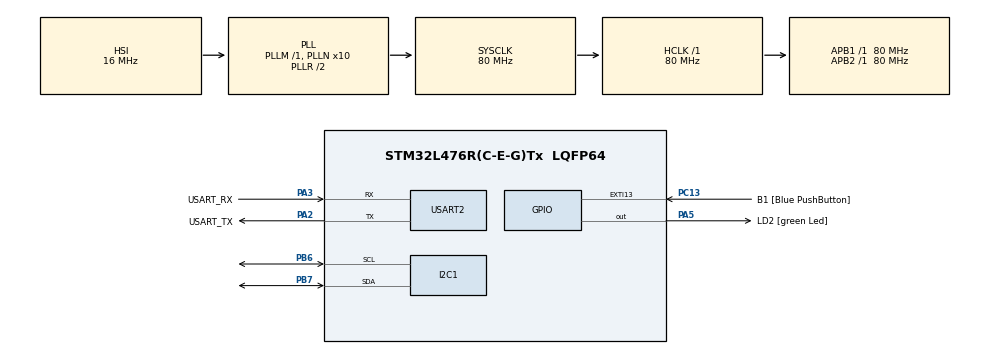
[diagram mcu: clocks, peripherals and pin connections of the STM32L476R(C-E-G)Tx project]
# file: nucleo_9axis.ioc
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Mcu.Family=STM32L4
Mcu.Name=STM32L476R(C-E-G)Tx
Mcu.Package=LQFP64
NVIC.PriorityGroup=NVIC_PRIORITYGROUP_4
PA13\ (JTMS-SWDIO).GPIO_Label=TMS
PA13\ (JTMS-SWDIO).Mode=Serial_Wire
PA13\ (JTMS-SWDIO).Signal=SYS_JTMS-SWDIO
PA14\ (JTCK-SWCLK).GPIO_Label=TCK
PA14\ (JTCK-SWCLK).Mode=Serial_Wire
PA14\ (JTCK-SWCLK).Signal=SYS_JTCK-SWCLK
PA2.GPIO_Label=USART_TX
PA2.GPIO_Mode=GPIO_MODE_AF_PP
PA2.GPIO_PuPd=GPIO_NOPULL
PA2.GPIO_Speed=GPIO_SPEED_FREQ_VERY_HIGH
PA2.Mode=Asynchronous
PA2.Signal=USART2_TX
PA3.GPIO_Label=USART_RX
PA3.GPIO_Mode=GPIO_MODE_AF_PP
PA3.GPIO_PuPd=GPIO_NOPULL
PA3.GPIO_Speed=GPIO_SPEED_FREQ_VERY_HIGH
PA3.Mode=Asynchronous
PA3.Signal=USART2_RX
PA5.GPIO_Label=LD2 [green Led]
PA5.GPIO_ModeDefaultOutputPP=GPIO_MODE_OUTPUT_PP
PA5.GPIO_PuPd=GPIO_NOPULL
PA5.GPIO_Speed=GPIO_SPEED_FREQ_LOW
PA5.Signal=GPIO_Output
PB3\ (JTDO-TRACESWO).GPIO_Label=SWO
PB3\ (JTDO-TRACESWO).Signal=SYS_JTDO-SWO
PB6.Mode=I2C
PB6.Signal=I2C1_SCL
PB7.Mode=I2C
PB7.Signal=I2C1_SDA
PC13.GPIO_Label=B1 [Blue PushButton]
PC13.GPIO_ModeDefaultEXTI=GPIO_MODE_IT_FALLING
PC13.GPIO_PuPd=GPIO_NOPULL
PC13.Signal=GPXTI13
PC14-OSC32_IN\ (PC14).Mode=LSE-External-Oscillator
PC14-OSC32_IN\ (PC14).Signal=RCC_OSC32_IN
PC15-OSC32_OUT\ (PC15).Mode=LSE-External-Oscillator
PC15-OSC32_OUT\ (PC15).Signal=RCC_OSC32_OUT
PH0-OSC_IN\ (PH0).Signal=RCC_OSC_IN
PH1-OSC_OUT\ (PH1).Signal=RCC_OSC_OUT
ProjectManager.HeapSize=0x200
ProjectManager.StackSize=0x400
ProjectManager.TargetToolchain=Makefile
RCC.ADCFreq_Value=64000000
RCC.AHBFreq_Value=80000000
RCC.APB1Freq_Value=80000000
RCC.APB1TimFreq_Value=80000000
RCC.APB2Freq_Value=80000000
RCC.APB2TimFreq_Value=80000000
RCC.CortexFreq_Value=80000000
RCC.HCLKFreq_Value=80000000
RCC.HSE_VALUE=8000000
RCC.HSI_VALUE=16000000
RCC.MSI_VALUE=4000000
RCC.PLLN=10
RCC.PLLSourceVirtual=RCC_PLLSOURCE_HSI
RCC.PREFETCH_ENABLE=1
RCC.SYSCLKFreq_VALUE=80000000
RCC.SYSCLKSource=RCC_SYSCLKSOURCE_PLLCLK
RCC.USBFreq_Value=64000000
RCC.VCOOutputFreq_Value=160000000
USART2.VirtualMode-Asynchronous=VM_ASYNC
board=NUCLEO-L476RG

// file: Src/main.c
/**
  ******************************************************************************
  * @file           : main.c
  * @brief          : Main program body
  ******************************************************************************
  ** This notice applies to any and all portions of this file
  * that are not between comment pairs USER CODE BEGIN and
  * USER CODE END. Other portions of this file, whether
  * inserted by the user or by software development tools
  * are owned by their respective copyright owners.
  *
  * COPYRIGHT(c) 2018 STMicroelectronics
  *
  * Redistribution and use in source and binary forms, with or without modification,
  * are permitted provided that the following conditions are met:
  *   1. Redistributions of source code must retain the above copyright notice,
  *      this list of conditions and the following disclaimer.
  *   2. Redistributions in binary form must reproduce the above copyright notice,
  *      this list of conditions and the following disclaimer in the documentation
  *      and/or other materials provided with the distribution.
  *   3. Neither the name of STMicroelectronics nor the names of its contributors
  *      may be used to endorse or promote products derived from this software
  *      without specific prior written permission.
  *
  * THIS SOFTWARE IS PROVIDED BY THE COPYRIGHT HOLDERS AND CONTRIBUTORS "AS IS"
  * AND ANY EXPRESS OR IMPLIED WARRANTIES, INCLUDING, BUT NOT LIMITED TO, THE
  * IMPLIED WARRANTIES OF MERCHANTABILITY AND FITNESS FOR A PARTICULAR PURPOSE ARE
  * DISCLAIMED. IN NO EVENT SHALL THE COPYRIGHT HOLDER OR CONTRIBUTORS BE LIABLE
  * FOR ANY DIRECT, INDIRECT, INCIDENTAL, SPECIAL, EXEMPLARY, OR CONSEQUENTIAL
  * DAMAGES (INCLUDING, BUT NOT LIMITED TO, PROCUREMENT OF SUBSTITUTE GOODS OR
  * SERVICES; LOSS OF USE, DATA, OR PROFITS; OR BUSINESS INTERRUPTION) HOWEVER
  * CAUSED AND ON ANY THEORY OF LIABILITY, WHETHER IN CONTRACT, STRICT LIABILITY,
  * OR TORT (INCLUDING NEGLIGENCE OR OTHERWISE) ARISING IN ANY WAY OUT OF THE USE
  * OF THIS SOFTWARE, EVEN IF ADVISED OF THE POSSIBILITY OF SUCH DAMAGE.
  *
  ******************************************************************************
  */
#include "main.h"
#include "stm32l4xx_hal.h"

/* USER CODE BEGIN Includes */
#include <stdio.h>
#include <string.h>
#include <math.h>
/* USER CODE END Includes */

I2C_HandleTypeDef hi2c1;

UART_HandleTypeDef huart2;

/* USER CODE BEGIN PV */
/* Private variables ---------------------------------------------------------*/
#define Addr_Accl 0x19
#define I2C_BUF_SIZE 100

float xAccl = 0.00;
float yAccl = 0.00;
float zAccl = 0.00;

/* USER CODE END PV */

uint8_t r_data = 0;
uint8_t r_data2 = 0;

char k[I2C_BUF_SIZE];
char s[I2C_BUF_SIZE];

void SystemClock_Config(void);
static void MX_GPIO_Init(void);
static void MX_USART2_UART_Init(void);
static void MX_I2C1_Init(void);

void BMX_Init(void);
void BMX_Accl(void);
void BMX_Set_Shadow_dis(_Bool);
_Bool BMX_Check_connection(void);
void Show_float(float);

int main(void)
{

  /* MCU Configuration----------------------------------------------------------*/

  /* Reset of all peripherals, Initializes the Flash interface and the Systick. */
  HAL_Init();

  /* Configure the system clock */
  SystemClock_Config();

  /* Initialize all configured peripherals */
  MX_GPIO_Init();
  MX_USART2_UART_Init();
  MX_I2C1_Init();
  /* USER CODE BEGIN 2 */
  BMX_Init();
  BMX_Check_connection();
  /* USER CODE END 2 */

  /* Infinite loop */
  /* USER CODE BEGIN WHILE */

  while (1)
  {
   BMX_Accl();
   Show_float(xAccl);
   Show_float(yAccl);
   Show_float(zAccl);
   HAL_Delay(1000);
  }
}

/** BMX Init*/
void BMX_Init(void){
// init x axis

//select PMU band width resisiter and set to 7.81 Hz
uint16_t Mem_PMU_BW = 0x10;
uint8_t p_BW = 0x08;
HAL_I2C_Mem_Write(&hi2c1,Addr_Accl<<1,Mem_PMU_BW,1,&p_BW,1,100);
HAL_Delay(100);

//select PMU range resisiter and set to -2
uint16_t Mem_PMU_Range = 0x0F;
uint8_t p_Range = 0x03;
HAL_I2C_Mem_Write(&hi2c1,Addr_Accl<<1,Mem_PMU_Range,1,&p_Range,1,100);
HAL_Delay(100);

//select PMU LPW resisiter and Normal mode
uint16_t Mem_PMU_LPW = 0x11;
uint8_t p_LPW = 0x00;
HAL_I2C_Mem_Write(&hi2c1,Addr_Accl<<1,Mem_PMU_LPW,1,&p_LPW,1,100);
HAL_Delay(100);
}

// BMX read Acceleration
void BMX_Accl(void){
  uint8_t xAccl_MSB;
  uint8_t xAccl_LSB;
  uint8_t yAccl_MSB;
  uint8_t yAccl_LSB;
  uint8_t zAccl_MSB;
  uint8_t zAccl_LSB;

  uint8_t Mem_xLSB = 0x02;
  uint8_t Mem_xMSB = 0x03;
  uint8_t Mem_yLSB = 0x04;
  uint8_t Mem_yMSB = 0x05;
  uint8_t Mem_zLSB = 0x06;
  uint8_t Mem_zMSB = 0x07;

  _Bool is_available = 1;
  _Bool is_unavailable = 0;

  HAL_I2C_Mem_Read(&hi2c1,Addr_Accl<<1,Mem_xLSB,1,&xAccl_LSB,1,100);
  BMX_Set_Shadow_dis(is_available);
  HAL_I2C_Mem_Read(&hi2c1,Addr_Accl<<1,Mem_xMSB,1,&xAccl_MSB,1,100);
  BMX_Set_Shadow_dis(is_unavailable);

  HAL_I2C_Mem_Read(&hi2c1,Addr_Accl<<1,Mem_yLSB,1,&yAccl_LSB,1,100);
  BMX_Set_Shadow_dis(is_available);
  HAL_I2C_Mem_Read(&hi2c1,Addr_Accl<<1,Mem_yMSB,1,&yAccl_MSB,1,100);
  BMX_Set_Shadow_dis(is_unavailable);

  HAL_I2C_Mem_Read(&hi2c1,Addr_Accl<<1,Mem_zLSB,1,&zAccl_LSB,1,100);
  BMX_Set_Shadow_dis(is_available);
  HAL_I2C_Mem_Read(&hi2c1,Addr_Accl<<1,Mem_zMSB,1,&zAccl_MSB,1,100);
  BMX_Set_Shadow_dis(is_unavailable);

  xAccl = ((xAccl_MSB*256) + (xAccl_LSB & 0xF0))/16;
  if(xAccl>2047) xAccl -= 4096;
  yAccl = ((yAccl_MSB*256) + (yAccl_LSB & 0xF0))/16;
  if(yAccl>2047) yAccl -= 4096;
  xAccl = ((zAccl_MSB*256) + (zAccl_LSB & 0xF0))/16;
  if(zAccl>2047) zAccl -= 4096;

  xAccl = xAccl*0.0098;
  yAccl = yAccl*0.0098;
  zAccl = zAccl*0.0098;
}

void BMX_Set_Shadow_dis(_Bool status){
  uint8_t Shadow_dis = 0x13;
  uint8_t SetValue;

  if (status == 1) SetValue = 0b00000000;
  else if ( status == 0) SetValue =  0b01000000;
  HAL_I2C_Mem_Write(&hi2c1,Addr_Accl<<1,Shadow_dis,1,&SetValue,1,100);
}

_Bool BMX_Check_connection(void){
  uint8_t r_data;
  char buff[I2C_BUF_SIZE];

  HAL_I2C_Mem_Read(&hi2c1,Addr_Accl<<1,0x00,1,&r_data,1,100);
  if (r_data == 0xFA) sprintf(buff,"Connection available\n",r_data);
  else if (r_data != 0xFA) sprintf(buff,"Connection unavailable\n",r_data);
  HAL_UART_Transmit (&huart2,(uint8_t*)(&buff[0]),strlen(&k[0]),100);
}

void Show_float(float value){
  char *tempsign = (value < 0) ? "-":"";
  double tempval = (value<0) ? -1*value:value;
  int tempInt1 = (int)tempval;
  float tempfrac = tempval - tempInt1;
  int tempInt2 = trunc(tempfrac*100000);

  sprintf(s,"Accl = %s%d.%04d\n",tempsign,tempInt1,tempInt2);
  HAL_UART_Transmit (&huart2,(uint8_t*)(&s[0]),strlen(&s[0]),100);
}

void SystemClock_Config(void)
{

  RCC_OscInitTypeDef RCC_OscInitStruct;
  RCC_ClkInitTypeDef RCC_ClkInitStruct;
  RCC_PeriphCLKInitTypeDef PeriphClkInit;

    /**Initializes the CPU, AHB and APB busses clocks
    */
  RCC_OscInitStruct.OscillatorType = RCC_OSCILLATORTYPE_HSI;
  RCC_OscInitStruct.HSIState = RCC_HSI_ON;
  RCC_OscInitStruct.HSICalibrationValue = 16;
  RCC_OscInitStruct.PLL.PLLState = RCC_PLL_ON;
  RCC_OscInitStruct.PLL.PLLSource = RCC_PLLSOURCE_HSI;
  RCC_OscInitStruct.PLL.PLLM = 1;
  RCC_OscInitStruct.PLL.PLLN = 10;
  RCC_OscInitStruct.PLL.PLLP = RCC_PLLP_DIV7;
  RCC_OscInitStruct.PLL.PLLQ = RCC_PLLQ_DIV2;
  RCC_OscInitStruct.PLL.PLLR = RCC_PLLR_DIV2;
  if (HAL_RCC_OscConfig(&RCC_OscInitStruct) != HAL_OK)
  {
    _Error_Handler(__FILE__, __LINE__);
  }

    /**Initializes the CPU, AHB and APB busses clocks
    */
  RCC_ClkInitStruct.ClockType = RCC_CLOCKTYPE_HCLK|RCC_CLOCKTYPE_SYSCLK
                              |RCC_CLOCKTYPE_PCLK1|RCC_CLOCKTYPE_PCLK2;
  RCC_ClkInitStruct.SYSCLKSource = RCC_SYSCLKSOURCE_PLLCLK;
  RCC_ClkInitStruct.AHBCLKDivider = RCC_SYSCLK_DIV1;
  RCC_ClkInitStruct.APB1CLKDivider = RCC_HCLK_DIV1;
  RCC_ClkInitStruct.APB2CLKDivider = RCC_HCLK_DIV1;

  if (HAL_RCC_ClockConfig(&RCC_ClkInitStruct, FLASH_LATENCY_4) != HAL_OK)
  {
    _Error_Handler(__FILE__, __LINE__);
  }

  PeriphClkInit.PeriphClockSelection = RCC_PERIPHCLK_USART2|RCC_PERIPHCLK_I2C1;
  PeriphClkInit.Usart2ClockSelection = RCC_USART2CLKSOURCE_PCLK1;
  PeriphClkInit.I2c1ClockSelection = RCC_I2C1CLKSOURCE_PCLK1;
  if (HAL_RCCEx_PeriphCLKConfig(&PeriphClkInit) != HAL_OK)
  {
    _Error_Handler(__FILE__, __LINE__);
  }

    /**Configure the main internal regulator output voltage
    */
  if (HAL_PWREx_ControlVoltageScaling(PWR_REGULATOR_VOLTAGE_SCALE1) != HAL_OK)
  {
    _Error_Handler(__FILE__, __LINE__);
  }

    /**Configure the Systick interrupt time
    */
  HAL_SYSTICK_Config(HAL_RCC_GetHCLKFreq()/1000);

    /**Configure the Systick
    */
  HAL_SYSTICK_CLKSourceConfig(SYSTICK_CLKSOURCE_HCLK);

  /* SysTick_IRQn interrupt configuration */
  HAL_NVIC_SetPriority(SysTick_IRQn, 0, 0);
}

/* I2C1 init function */
static void MX_I2C1_Init(void)
{

  hi2c1.Instance = I2C1;
  hi2c1.Init.Timing = 0x10909CEC;
  hi2c1.Init.OwnAddress1 = 0;
  hi2c1.Init.AddressingMode = I2C_ADDRESSINGMODE_7BIT;
  hi2c1.Init.DualAddressMode = I2C_DUALADDRESS_DISABLE;
  hi2c1.Init.OwnAddress2 = 0;
  hi2c1.Init.OwnAddress2Masks = I2C_OA2_NOMASK;
  hi2c1.Init.GeneralCallMode = I2C_GENERALCALL_DISABLE;
  hi2c1.Init.NoStretchMode = I2C_NOSTRETCH_DISABLE;
  if (HAL_I2C_Init(&hi2c1) != HAL_OK)
  {
    _Error_Handler(__FILE__, __LINE__);
  }

    /**Configure Analogue filter
    */
  if (HAL_I2CEx_ConfigAnalogFilter(&hi2c1, I2C_ANALOGFILTER_ENABLE) != HAL_OK)
  {
    _Error_Handler(__FILE__, __LINE__);
  }

    /**Configure Digital filter
    */
  if (HAL_I2CEx_ConfigDigitalFilter(&hi2c1, 0) != HAL_OK)
  {
    _Error_Handler(__FILE__, __LINE__);
  }

}

/* USART2 init function */
static void MX_USART2_UART_Init(void)
{

  huart2.Instance = USART2;
  huart2.Init.BaudRate = 115200;
  huart2.Init.WordLength = UART_WORDLENGTH_8B;
  huart2.Init.StopBits = UART_STOPBITS_1;
  huart2.Init.Parity = UART_PARITY_NONE;
  huart2.Init.Mode = UART_MODE_TX_RX;
  huart2.Init.HwFlowCtl = UART_HWCONTROL_NONE;
  huart2.Init.OverSampling = UART_OVERSAMPLING_16;
  huart2.Init.OneBitSampling = UART_ONE_BIT_SAMPLE_DISABLE;
  huart2.AdvancedInit.AdvFeatureInit = UART_ADVFEATURE_NO_INIT;
  if (HAL_UART_Init(&huart2) != HAL_OK)
  {
    _Error_Handler(__FILE__, __LINE__);
  }

}

/** Configure pins as
        * Analog
        * Input
        * Output
        * EVENT_OUT
        * EXTI
*/
static void MX_GPIO_Init(void)
{

  GPIO_InitTypeDef GPIO_InitStruct;

  /* GPIO Ports Clock Enable */
  __HAL_RCC_GPIOC_CLK_ENABLE();
  __HAL_RCC_GPIOH_CLK_ENABLE();
  __HAL_RCC_GPIOA_CLK_ENABLE();
  __HAL_RCC_GPIOB_CLK_ENABLE();

  /*Configure GPIO pin Output Level */
  HAL_GPIO_WritePin(LD2_GPIO_Port, LD2_Pin, GPIO_PIN_RESET);

  /*Configure GPIO pin : B1_Pin */
  GPIO_InitStruct.Pin = B1_Pin;
  GPIO_InitStruct.Mode = GPIO_MODE_IT_FALLING;
  GPIO_InitStruct.Pull = GPIO_NOPULL;
  HAL_GPIO_Init(B1_GPIO_Port, &GPIO_InitStruct);

  /*Configure GPIO pin : LD2_Pin */
  GPIO_InitStruct.Pin = LD2_Pin;
  GPIO_InitStruct.Mode = GPIO_MODE_OUTPUT_PP;
  GPIO_InitStruct.Pull = GPIO_NOPULL;
  GPIO_InitStruct.Speed = GPIO_SPEED_FREQ_LOW;
  HAL_GPIO_Init(LD2_GPIO_Port, &GPIO_InitStruct);

}

void _Error_Handler(char *file, int line)
{
  while(1)
  {
  }
}

/************************ (C) COPYRIGHT STMicroelectronics *****END OF FILE****/
